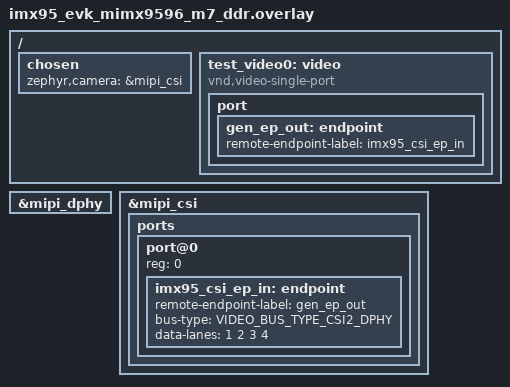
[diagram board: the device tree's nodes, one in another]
/*
 * Copyright (c) 2026 NXP
 * SPDX-License-Identifier: Apache-2.0
 */

#include <zephyr/dt-bindings/video/video-interfaces.h>

/ {
	chosen {
		/* Not used by this test, but required by some samples. */
		zephyr,camera = &mipi_csi;
	};

	test_video0: video {
		compatible = "vnd,video-single-port";
		status = "okay";

		port {
			gen_ep_out: endpoint {
				remote-endpoint-label = "imx95_csi_ep_in";
			};
		};
	};
};

&mipi_dphy {
	status = "okay";
};

&mipi_csi {
	status = "okay";

	ports {
		#address-cells = <1>;
		#size-cells = <0>;

		port@0 {
			reg = <0>;

			imx95_csi_ep_in: endpoint {
				remote-endpoint-label = "gen_ep_out";
				bus-type = <VIDEO_BUS_TYPE_CSI2_DPHY>;
				data-lanes = <1 2 3 4>;
			};
		};
	};
};
